# STM32G041xx register map
File version: 1.0
Registers are 32-bit, read-write, reset 0x0 unless marked. A register's access mark holds for its fields unless they carry their own. Offsets are from the block's base; lines under a group give offsets from that group; [hi:lo] are bit positions; {n}, {i} and the like mark numbered series; 'fields as' and 'values as' point back to an identical list; <NAME> marks a mode.

## Memory map
0x40000000 TIM2 — TIM
0x40000400 TIM3 — TIM
0x40002000 TIM14 — TIM
0x40002800 RTC — Real-Time Clock
0x40002C00 WWDG — Window WATCHDOG
0x40003000 IWDG — Independent WATCHDOG
0x40003800 SPI2 — Serial Peripheral Interface
0x40004400 USART2 — Universal Synchronous Asynchronous Receiver Transmitter
0x40005400 I2C1 — Inter-integrated Circuit Interface
0x40005800 I2C2 — Inter-integrated Circuit Interface
0x40007000 PWR — Power Control
0x40007C00 LPTIM1 — LPTIMER
0x40008000 LPUART1 — Universal Synchronous Asynchronous Receiver Transmitter
0x40009400 LPTIM2 — LPTIMER
0x4000B000 TAMP — Tamper and backup registers
0x40010000 SYSCFG — System configuration controller
0x40010030 VREFBUF
0x40012400 ADC1 — Analog to Digital Converter
0x40012C00 TIM1 — TIM
0x40013000 SPI1 — Serial Peripheral Interface
0x40013800 USART1 — Universal Synchronous Asynchronous Receiver Transmitter
0x40014400 TIM16 — TIM
0x40014800 TIM17 — TIM
0x40015800 DBG — Debug MCU
0x40020000 DMA1
0x40020800 DMAMUX1 — DMA Multiplexer
0x40021000 RCC — Reset and Clock Control
0x40021800 EXTI — Asynch Interrupt/Event Controller (EXTI)
0x40022000 FLASH — FLASH Registers
0x40023000 CRC — CRC calculation unit
0x40025000 RNG
0x40026000 AES — AES hardware accelerator
0x40026000 AES1 — AES hardware accelerator
0x50000000 GPIOA — General Purpose I/O
0x50000400 GPIOB — General Purpose I/O
0x50000800 GPIOC — General Purpose I/O
0x50000C00 GPIOD — General Purpose I/O
0x50001400 GPIOF — General Purpose I/O

## Interrupts
0 WWDG — Window WatchDog Interrupt
2 RTC_TAMP (RTC, TAMP) — RTC interrupt through the EXTI line 19 & 21
3 FLASH — FLASH global Interrupt
4 RCC — RCC global Interrupt
5 EXTI0_1 (EXTI) — EXTI 0 and 1 Interrupts
6 EXTI2_3 (EXTI) — EXTI Line 2 and 3 Interrupts
7 EXTI4_15 (EXTI) — EXTI Line 4 to 15 Interrupts
9 DMA1_Channel1 (DMA1) — DMA1 Channel 1 Interrupt
10 DMA1_Channel2_3 (DMA1) — DMA1 Channel 2 and Channel 3 Interrupts
11 DMA1_Ch4_5_DMAMUX1_OVR (DMA1, DMAMUX1) — DMA1 Channel 4 to Channel 5 and DMAMUX1 Overrun Interrupts
12 ADC1 — ADC1 Interrupts
13 TIM1_BRK_UP_TRG_COM (TIM1) — TIM1 Break, Update, Trigger and Commutation Interrupts
14 TIM1_CC (TIM1) — TIM1 Capture Compare Interrupt
15 TIM2 — TIM2 Interrupt
16 TIM3 — TIM3 global Interrupt
17 LPTIM1 — LPTIM1 global Interrupts
18 LPTIM2 — LPTIM2 global Interrupt
19 TIM14 — TIM14 global Interrupt
21 TIM16 — TIM16 global Interrupt
22 TIM17 — TIM17 global Interrupt
23 I2C1 — I2C1 Interrupt (combined with EXTI 23)
24 I2C2 — I2C2 Interrupt
25 SPI1 — SPI1/I2S1 Interrupt
26 SPI2 — SPI2 Interrupt
27 USART1 — USART1 Interrupt
28 USART2 — USART2 Interrupt
29 LPUART1 — LPUART1 globlal Interrupts (combined with EXTI 28)
31 AES_RNG (RNG, AES) — AES & RNG Interrupt

## WWDG — Window WATCHDOG
Base 0x40002C00
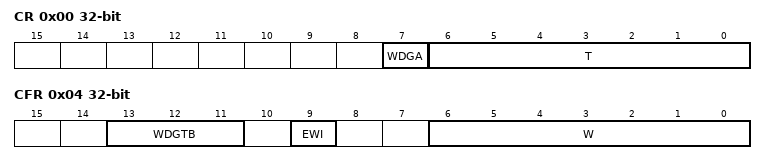
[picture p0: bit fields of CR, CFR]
0x00 CR — WWDG Control register
  [7] WDGA — Activation bit
  [6:0] T — T[6:0] bits (7-Bit counter (MSB to LSB))
0x04 CFR — WWDG Configuration register
  [13:11] WDGTB — WDGTB[2:0] bits (Timer Base)
    0=PRESCALER_1 (WWDG counter clock = (PCLK1/4096)/1); 1=PRESCALER_2 (WWDG counter clock = (PCLK1/4096)/2); 2=PRESCALER_4 (WWDG counter clock = (PCLK1/4096)/4); 3=PRESCALER_8 (WWDG counter clock = (PCLK1/4096)/8); 4=PRESCALER_16 (WWDG counter clock = (PCLK1/4096)/16); 5=PRESCALER_32 (WWDG counter clock = (PCLK1/4096)/32); 6=PRESCALER_64 (WWDG counter clock = (PCLK1/4096)/64); 7=PRESCALER_128 (WWDG counter clock = (PCLK1/4096)/128)
  [9] EWI — Early Wakeup Interrupt
  [6:0] W — W[6:0] bits (7-bit window value)
0x08 SR — WWDG Status register
  [0] EWIF — Early Wakeup Interrupt Flag

## IWDG — Independent WATCHDOG
Base 0x40003000
0x00 KR — IWDG Key register
  [15:0] KEY — Key value (write only, read 0000h)
0x04 PR — IWDG Prescaler register
  [2:0] PR — PR[2:0] (Prescaler divider)
0x08 RLR — IWDG Reload register
  [11:0] RL — Watchdog counter reload value
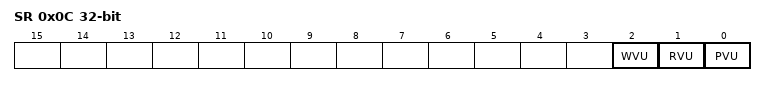
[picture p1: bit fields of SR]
0x0C SR — IWDG Status register
  [2] WVU — Watchdog counter window value update
  [1] RVU — Watchdog counter reload value update
  [0] PVU — Watchdog prescaler value update
0x10 WINR — IWDG Window register
  [11:0] WIN — Watchdog counter window value
